VERSION ""

NS_ :

BS_:

BU_: JETSON_SBG

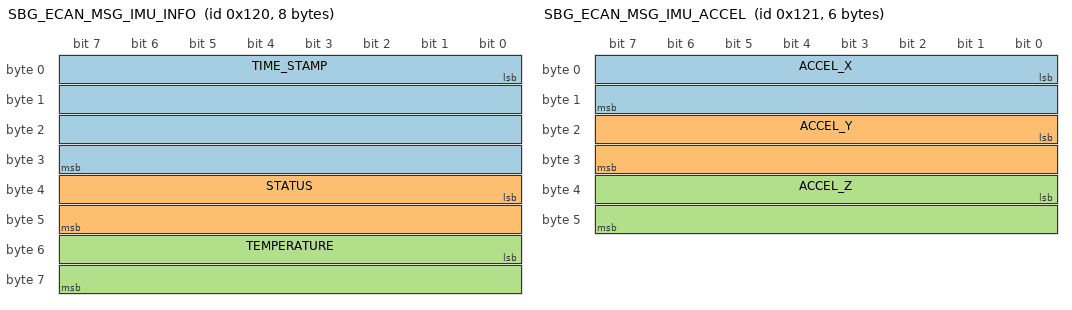
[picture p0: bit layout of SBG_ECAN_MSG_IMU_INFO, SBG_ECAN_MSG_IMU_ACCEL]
BO_ 288 SBG_ECAN_MSG_IMU_INFO: 8 JETSON_SBG
 SG_ TIME_STAMP : 0|32@1+ (1,0) [0|4294967295] "us" Vector__XXX
 SG_ STATUS : 32|16@1+ (1,0) [0|65535] "" Vector__XXX
 SG_ TEMPERATURE : 48|16@1- (0.01,0) [-327.68|327.67] "degC" Vector__XXX

BO_ 289 SBG_ECAN_MSG_IMU_ACCEL: 6 JETSON_SBG
 SG_ ACCEL_X : 0|16@1- (0.01,0) [-327.68|327.67] "m/s^2" Vector__XXX
 SG_ ACCEL_Y : 16|16@1- (0.01,0) [-327.68|327.67] "m/s^2" Vector__XXX
 SG_ ACCEL_Z : 32|16@1- (0.01,0) [-327.68|327.67] "m/s^2" Vector__XXX

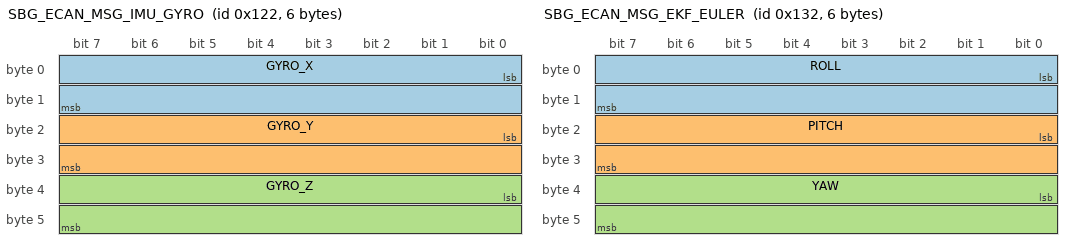
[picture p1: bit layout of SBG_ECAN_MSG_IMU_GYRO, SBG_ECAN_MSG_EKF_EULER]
BO_ 290 SBG_ECAN_MSG_IMU_GYRO: 6 JETSON_SBG
 SG_ GYRO_X : 0|16@1- (0.001,0) [-32.768|32.767] "rad/s" Vector__XXX
 SG_ GYRO_Y : 16|16@1- (0.001,0) [-32.768|32.767] "rad/s" Vector__XXX
 SG_ GYRO_Z : 32|16@1- (0.001,0) [-32.768|32.767] "rad/s" Vector__XXX

BO_ 304 SBG_ECAN_MSG_EKF_INFO: 4 JETSON_SBG
 SG_ TIME_STAMP : 0|32@1+ (1,0) [0|4294967295] "us" Vector__XXX

BO_ 306 SBG_ECAN_MSG_EKF_EULER: 6 JETSON_SBG
 SG_ ROLL : 0|16@1- (0.0001,0) [-3.2768|3.2767] "rad" Vector__XXX
 SG_ PITCH : 16|16@1- (0.0001,0) [-3.2768|3.2767] "rad" Vector__XXX
 SG_ YAW : 32|16@1- (0.0001,0) [-3.2768|3.2767] "rad" Vector__XXX

BO_ 308 SBG_ECAN_MSG_EKF_POS: 8 JETSON_SBG
 SG_ LATITUDE : 0|32@1- (1E-7,0) [-214.7483648|214.7483647] "deg" Vector__XXX
 SG_ LONGITUDE : 32|32@1- (1E-7,0) [-214.7483648|214.7483647] "deg" Vector__XXX

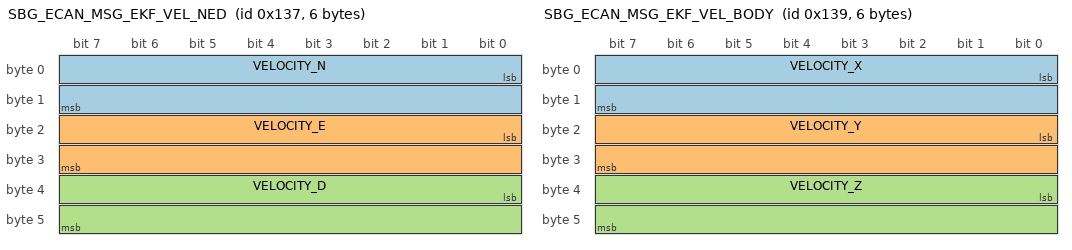
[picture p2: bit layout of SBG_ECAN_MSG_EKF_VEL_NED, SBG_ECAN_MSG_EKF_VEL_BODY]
BO_ 311 SBG_ECAN_MSG_EKF_VEL_NED: 6 JETSON_SBG
 SG_ VELOCITY_N : 0|16@1- (0.01,0) [-327.68|327.67] "m/s" Vector__XXX
 SG_ VELOCITY_E : 16|16@1- (0.01,0) [-327.68|327.67] "m/s" Vector__XXX
 SG_ VELOCITY_D : 32|16@1- (0.01,0) [-327.68|327.67] "m/s" Vector__XXX

BO_ 313 SBG_ECAN_MSG_EKF_VEL_BODY: 6 JETSON_SBG
 SG_ VELOCITY_X : 0|16@1- (0.01,0) [-327.68|327.67] "m/s" Vector__XXX
 SG_ VELOCITY_Y : 16|16@1- (0.01,0) [-327.68|327.67] "m/s" Vector__XXX
 SG_ VELOCITY_Z : 32|16@1- (0.01,0) [-327.68|327.67] "m/s" Vector__XXX

BO_ 373 SBG_ECAN_MSG_GPS1_POS: 8 JETSON_SBG
 SG_ LATITUDE : 0|32@1- (1E-7,0) [-214.7483648|214.7483647] "deg" Vector__XXX
 SG_ LONGITUDE : 32|32@1- (1E-7,0) [-214.7483648|214.7483647] "deg" Vector__XXX

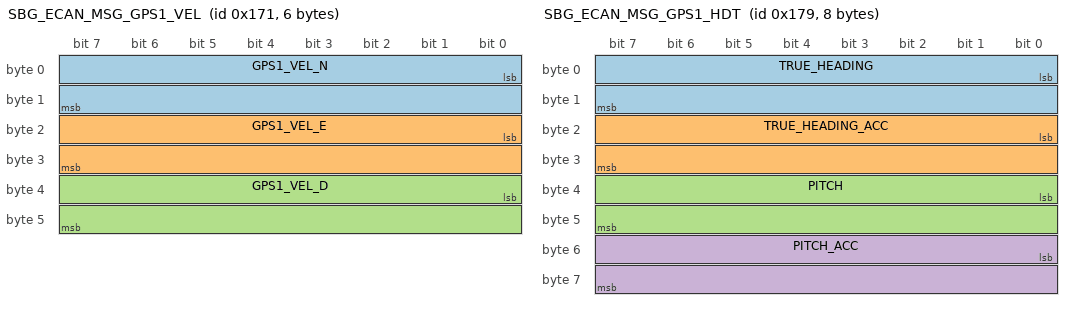
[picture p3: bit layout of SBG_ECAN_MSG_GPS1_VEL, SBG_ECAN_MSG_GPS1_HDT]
BO_ 369 SBG_ECAN_MSG_GPS1_VEL: 6 JETSON_SBG
 SG_ GPS1_VEL_N : 0|16@1- (0.01,0) [-327.68|327.67] "m/s" Vector__XXX
 SG_ GPS1_VEL_E : 16|16@1- (0.01,0) [-327.68|327.67] "m/s" Vector__XXX
 SG_ GPS1_VEL_D : 32|16@1- (0.01,0) [-327.68|327.67] "m/s" Vector__XXX

BO_ 377 SBG_ECAN_MSG_GPS1_HDT: 8 JETSON_SBG
 SG_ TRUE_HEADING : 0|16@1+ (0.01,0) [0|655.35] "deg" Vector__XXX
 SG_ TRUE_HEADING_ACC : 16|16@1+ (0.01,0) [0|655.35] "deg" Vector__XXX
 SG_ PITCH : 32|16@1- (0.01,0) [-327.68|327.67] "deg" Vector__XXX
 SG_ PITCH_ACC : 48|16@1+ (0.01,0) [0|655.35] "deg" Vector__XXX

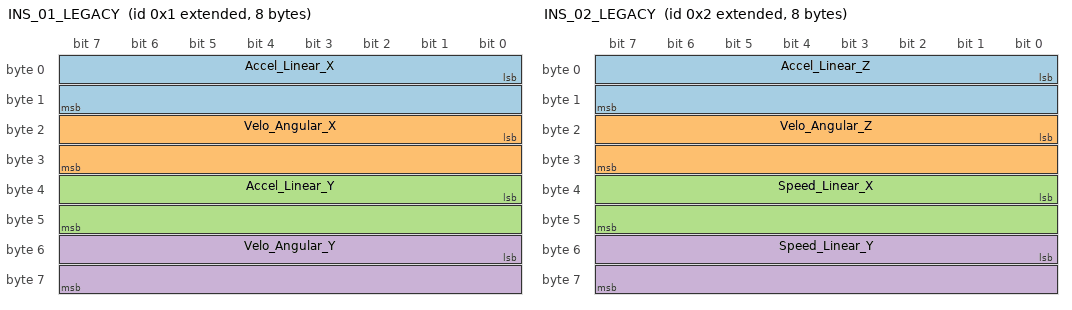
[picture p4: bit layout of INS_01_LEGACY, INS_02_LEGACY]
BO_ 2147483649 INS_01_LEGACY: 8 JETSON_SBG
 SG_ Accel_Linear_X : 0|16@1- (0.01,0) [-327.68|327.67] "m/s^2" Vector__XXX
 SG_ Velo_Angular_X : 16|16@1- (0.01,0) [-327.68|327.67] "rad/s" Vector__XXX
 SG_ Accel_Linear_Y : 32|16@1- (0.01,0) [-327.68|327.67] "m/s^2" Vector__XXX
 SG_ Velo_Angular_Y : 48|16@1- (0.01,0) [-327.68|327.67] "rad/s" Vector__XXX

BO_ 2147483650 INS_02_LEGACY: 8 JETSON_SBG
 SG_ Accel_Linear_Z : 0|16@1- (0.01,0) [-327.68|327.67] "m/s^2" Vector__XXX
 SG_ Velo_Angular_Z : 16|16@1- (0.01,0) [-327.68|327.67] "rad/s" Vector__XXX
 SG_ Speed_Linear_X : 32|16@1- (0.01,0) [-327.68|327.67] "m/s" Vector__XXX
 SG_ Speed_Linear_Y : 48|16@1- (0.01,0) [-327.68|327.67] "m/s" Vector__XXX

CM_ BO_ 288 "IDs e layout gerados diretamente do codigo sbg_to_can.py (funcao frame_imu_info). Frame STANDARD 11-bit, little-endian.";
CM_ SG_ 288 STATUS "Hardcoded para 0 no codigo atual - nao reflete dado real do SBG ainda.";
CM_ BO_ 289 "Gerado a partir de frame_imu_accel().";
CM_ BO_ 290 "Gerado a partir de frame_imu_gyro(). Fator real e 0.001 (nao 0.01 como um comentario antigo do script sugeria).";
CM_ BO_ 304 "Gerado a partir de frame_ekf_info().";
CM_ BO_ 306 "Gerado a partir de frame_ekf_euler().";
CM_ BO_ 308 "Gerado a partir de frame_ekf_pos(). Range no DBC reflete o clamp do codigo (int32 completo); faixa fisica real de lat/lon e -90/90 e -180/180.";
CM_ BO_ 311 "Gerado a partir de frame_ekf_vel_ned().";
CM_ BO_ 313 "SBG_ECAN_MSG_EKF_VEL_BODY (0x139): velocidade INS no frame do veiculo, conforme protocolo CAN SBG.";
CM_ BO_ 369 "SBG_ECAN_MSG_GPS1_VEL (0x171): velocidade GNSS NED do modulo 1, conforme protocolo CAN SBG.";
CM_ BO_ 373 "Gerado a partir de frame_gps1_pos(). Mesma ressalva de range de 308.";
CM_ BO_ 377 "Gerado a partir de frame_gps1_hdt().";
CM_ BO_ 2147483649 "Compatibilidade com pipeline/mock legado INS_01. O parser mascara bit 31, entao este BO_ mapeia CAN ID 0x1.";
CM_ BO_ 2147483650 "Compatibilidade com pipeline/mock legado INS_02. O parser mascara bit 31, entao este BO_ mapeia CAN ID 0x2.";
CM_ SG_ 377 TRUE_HEADING_ACC "Hardcoded para 0 no codigo atual.";
CM_ SG_ 377 PITCH_ACC "Hardcoded para 0 no codigo atual.";
